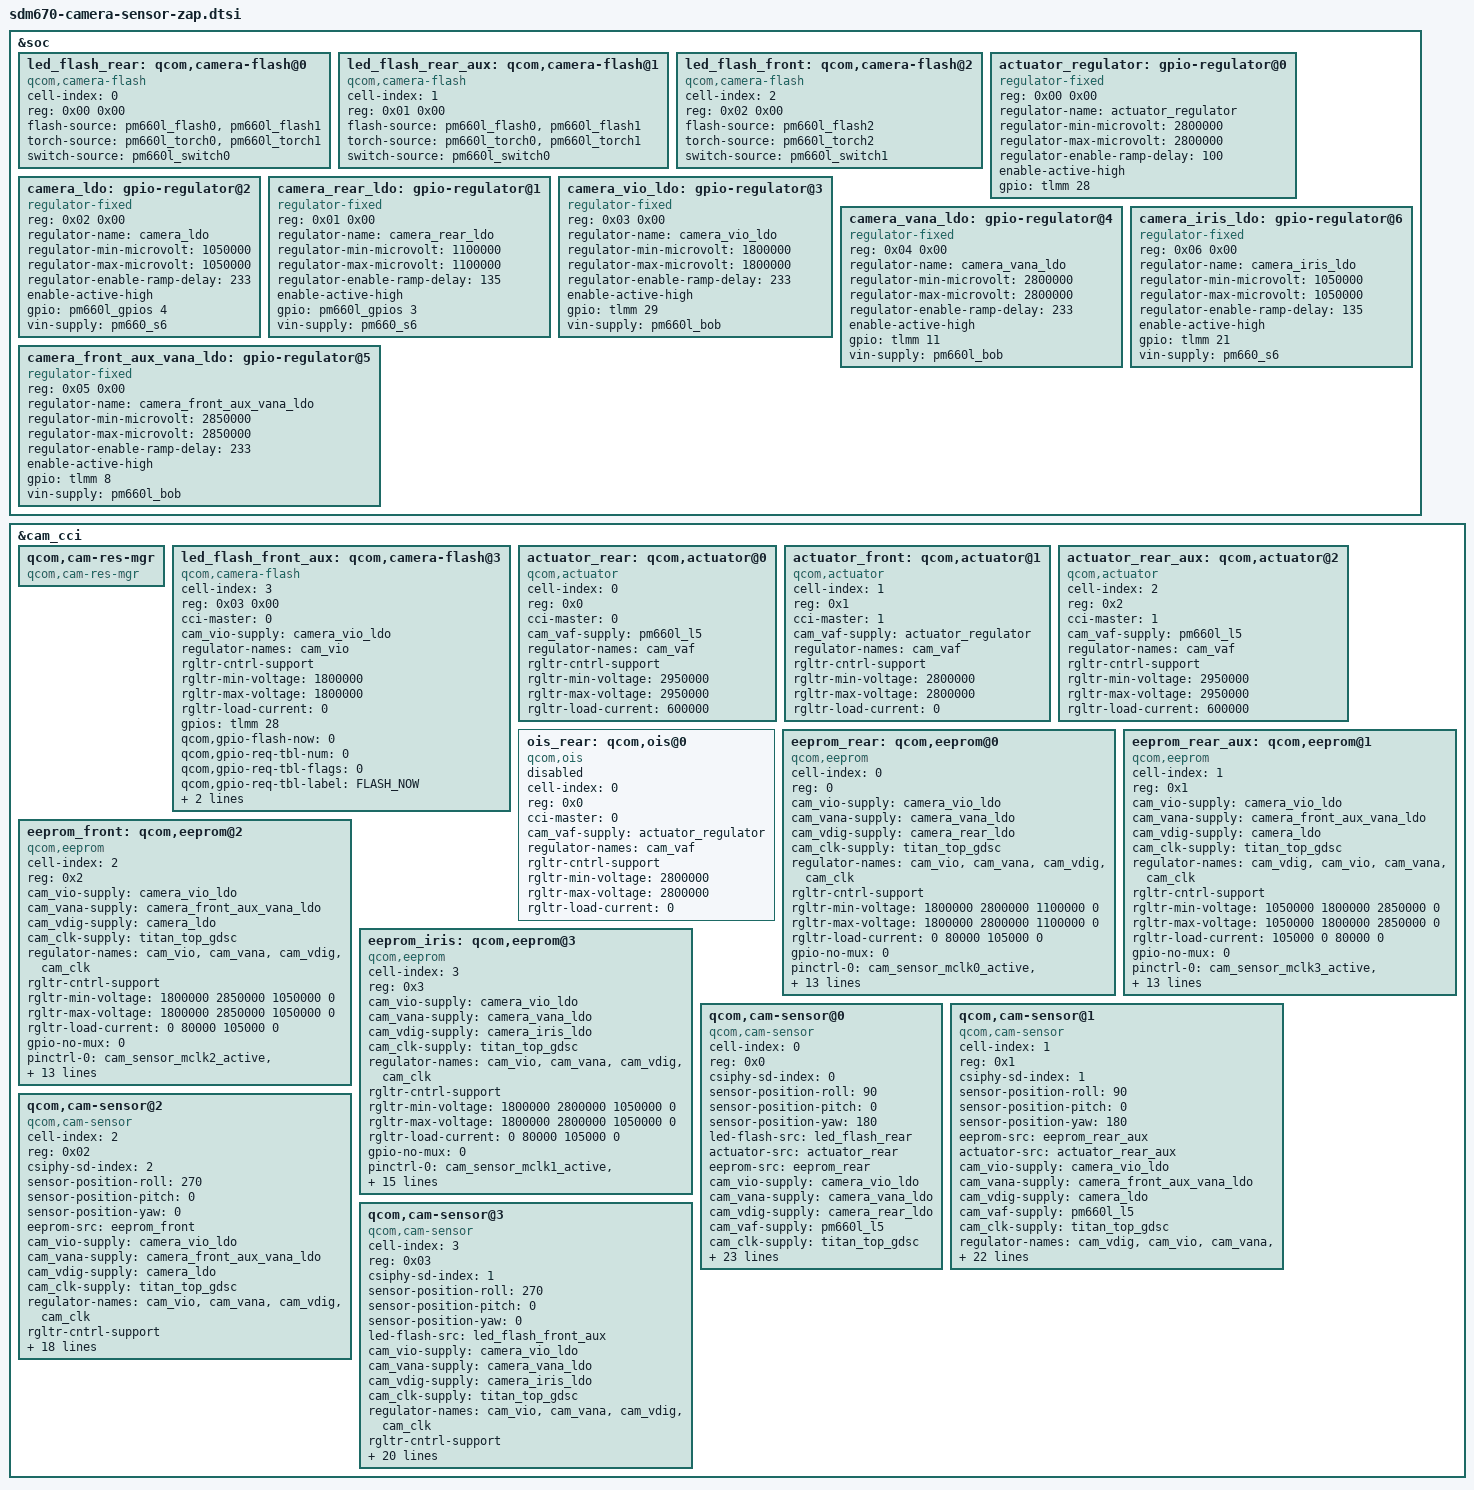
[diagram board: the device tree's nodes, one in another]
/*
 * Copyright (c) 2016-2018, The Linux Foundation. All rights reserved.
 *
 * This program is free software; you can redistribute it and/or modify
 * it under the terms of the GNU General Public License version 2 and
 * only version 2 as published by the Free Software Foundation.
 *
 * This program is distributed in the hope that it will be useful,
 * but WITHOUT ANY WARRANTY; without even the implied warranty of
 * MERCHANTABILITY or FITNESS FOR A PARTICULAR PURPOSE.  See the
 * GNU General Public License for more details.
 */

&soc {
/* Flash Led setting : start */
	led_flash_rear: qcom,camera-flash@0 {
		cell-index = <0>;
		reg = <0x00 0x00>;
		compatible = "qcom,camera-flash";
		flash-source = <&pm660l_flash0 &pm660l_flash1>;
		torch-source = <&pm660l_torch0 &pm660l_torch1>;
		switch-source = <&pm660l_switch0>;
		status = "ok";
	};

	led_flash_rear_aux: qcom,camera-flash@1 {
		cell-index = <1>;
		reg = <0x01 0x00>;
		compatible = "qcom,camera-flash";
		flash-source = <&pm660l_flash0 &pm660l_flash1>;
		torch-source = <&pm660l_torch0 &pm660l_torch1>;
		switch-source = <&pm660l_switch0>;
		status = "ok";
	};

	led_flash_front: qcom,camera-flash@2 {
		cell-index = <2>;
		reg = <0x02 0x00>;
		compatible = "qcom,camera-flash";
		flash-source = <&pm660l_flash2>;
		torch-source = <&pm660l_torch2>;
		switch-source = <&pm660l_switch1>;
		status = "ok";
	};
/*
	led_flash_iris: qcom,camera-flash@3 {
		cell-index = <3>;
		reg = <0x03 0x00>;
		compatible = "qcom,camera-flash";
		flash-source = <&pm660l_flash2>;
		torch-source = <&pm660l_torch2>;
		switch-source = <&pm660l_switch2>;
		status = "ok";
	};

*/
/* Flash Led setting : end */

/* actuator setting : start */
	actuator_regulator: gpio-regulator@0 {
		compatible = "regulator-fixed";
		reg = <0x00 0x00>;
		regulator-name = "actuator_regulator";
		regulator-min-microvolt = <2800000>;
		regulator-max-microvolt = <2800000>;
		regulator-enable-ramp-delay = <100>;
		enable-active-high;
		gpio = <&tlmm 28 0>;
	};
/* actuator setting : end */

/* Front&Aux DVDD : start */
	camera_ldo: gpio-regulator@2 {
		compatible = "regulator-fixed";
		reg = <0x02 0x00>;
		regulator-name = "camera_ldo";
		regulator-min-microvolt = <1050000>;
		regulator-max-microvolt = <1050000>;
		regulator-enable-ramp-delay = <233>;
		enable-active-high;
		gpio = <&pm660l_gpios 4 0>;
		/*pinctrl-names = "default";*/
		/*pinctrl-0 = <&camera_front_aux_dvdd_en_default>;*/
		vin-supply = <&pm660_s6>;
	};
/* Front&Aux DVDD : end */

/* Rear DVDD : start */
	camera_rear_ldo: gpio-regulator@1 {
		compatible = "regulator-fixed";
		reg = <0x01 0x00>;
		regulator-name = "camera_rear_ldo";
		regulator-min-microvolt = <1100000>;
		regulator-max-microvolt = <1100000>;
		regulator-enable-ramp-delay = <135>;
		enable-active-high;
		gpio = <&pm660l_gpios 3 0>;
		/*pinctrl-names = "default";*/
		/*pinctrl-0 = <&camera_rear_dvdd_en_default>;*/
		vin-supply = <&pm660_s6>;
	};
/* Rear DVDD : end */

/* all sensor DOVDD : start */
	camera_vio_ldo: gpio-regulator@3 {
		compatible = "regulator-fixed";
		reg = <0x03 0x00>;
		regulator-name = "camera_vio_ldo";
		regulator-min-microvolt = <1800000>;
		regulator-max-microvolt = <1800000>;
		regulator-enable-ramp-delay = <233>;
		enable-active-high;
		gpio = <&tlmm 29 0>;
		/*pinctrl-names = "default";*/
		/*pinctrl-0 = <&cam_sensor_rear_vio>;*/
		vin-supply = <&pm660l_bob>;
	};
/* all sensor DOVDD : end */

/* Rear&IR AVDD : start */
	camera_vana_ldo: gpio-regulator@4 {
		compatible = "regulator-fixed";
		reg = <0x04 0x00>;
		regulator-name = "camera_vana_ldo";
		regulator-min-microvolt = <2800000>;
		regulator-max-microvolt = <2800000>;
		regulator-enable-ramp-delay = <233>;
		enable-active-high;
		gpio = <&tlmm 11 0>;
		/*pinctrl-names = "default";*/
		/*pinctrl-0 = <&cam_sensor_rear_vana>;*/
		vin-supply = <&pm660l_bob>;
	};
/* Rear&IR AVDD : end */

/* Front&Aux AVDD : start */
	camera_front_aux_vana_ldo: gpio-regulator@5 {
		compatible = "regulator-fixed";
		reg = <0x05 0x00>;
		regulator-name = "camera_front_aux_vana_ldo";
		regulator-min-microvolt = <2850000>;
		regulator-max-microvolt = <2850000>;
		regulator-enable-ramp-delay = <233>;
		enable-active-high;
		gpio = <&tlmm 8 0>;
		/*pinctrl-names = "default";*/
		/*pinctrl-0 = <&cam_sensor_front_aux_vana>;*/
		vin-supply = <&pm660l_bob>;
	};
/* Front&Aux AVDD : end */

/* IR DVDD : start */
	camera_iris_ldo: gpio-regulator@6 {
		compatible = "regulator-fixed";
		reg = <0x06 0x00>;
		regulator-name = "camera_iris_ldo";
		regulator-min-microvolt = <1050000>;
		regulator-max-microvolt = <1050000>;
		regulator-enable-ramp-delay = <135>;
		enable-active-high;
		gpio = <&tlmm 21 0>;
		/*pinctrl-names = "default";*/
		/*pinctrl-0 = <&camera_rear_dvdd_en_default>;*/
		vin-supply = <&pm660_s6>;
	};
/* IR DVDD : end */
};

&cam_cci {
	qcom,cam-res-mgr {
		compatible = "qcom,cam-res-mgr";
		status = "ok";
	};

	led_flash_front_aux: qcom,camera-flash@3 {
		cell-index = <3>;
		reg = <0x03 0x00>;
		compatible = "qcom,camera-flash";
		cci-master = <0>;

        	cam_vio-supply = <&camera_vio_ldo>;
        	regulator-names = "cam_vio";
        	rgltr-cntrl-support;
        	rgltr-min-voltage = <1800000>;
        	rgltr-max-voltage = <1800000>;
        	rgltr-load-current = <0>;

		gpios = <&tlmm 28 0>;
		qcom,gpio-flash-now = <0>;
		qcom,gpio-req-tbl-num = <0>;
		qcom,gpio-req-tbl-flags = <0>;
		qcom,gpio-req-tbl-label = "FLASH_NOW";
		qcom,max-current = <1000>;
		qcom,max-duration = <1200>;
		status = "ok";
	};

	actuator_rear: qcom,actuator@0 {
		cell-index = <0>;
		reg = <0x0>;
		compatible = "qcom,actuator";
		cci-master = <0>;
		cam_vaf-supply = <&pm660l_l5>;
		regulator-names = "cam_vaf";
		rgltr-cntrl-support;
		rgltr-min-voltage = <2950000>;
		rgltr-max-voltage = <2950000>;
		rgltr-load-current = <600000>;
	};

	actuator_front: qcom,actuator@1 {
		cell-index = <1>;
		reg = <0x1>;
		compatible = "qcom,actuator";
		cci-master = <1>;
		cam_vaf-supply = <&actuator_regulator>;
		regulator-names = "cam_vaf";
		rgltr-cntrl-support;
		rgltr-min-voltage = <2800000>;
		rgltr-max-voltage = <2800000>;
		rgltr-load-current = <0>;
	};

	actuator_rear_aux: qcom,actuator@2 {
		cell-index = <2>;
		reg = <0x2>;
		compatible = "qcom,actuator";
		cci-master = <1>;
		cam_vaf-supply = <&pm660l_l5>;
		regulator-names = "cam_vaf";
		rgltr-cntrl-support;
		rgltr-min-voltage = <2950000>;
		rgltr-max-voltage = <2950000>;
		rgltr-load-current = <600000>;
	};

	ois_rear: qcom,ois@0 {
		cell-index = <0>;
		reg = <0x0>;
		compatible = "qcom,ois";
		cci-master = <0>;
		cam_vaf-supply = <&actuator_regulator>;
		regulator-names = "cam_vaf";
		rgltr-cntrl-support;
		rgltr-min-voltage = <2800000>;
		rgltr-max-voltage = <2800000>;
		rgltr-load-current = <0>;
		status = "disabled";
	};

	eeprom_rear: qcom,eeprom@0 {
		cell-index = <0>;
		reg = <0>;
		compatible = "qcom,eeprom";
		cam_vio-supply = <&camera_vio_ldo>;
		cam_vana-supply = <&camera_vana_ldo>;
		cam_vdig-supply = <&camera_rear_ldo>;
		cam_clk-supply = <&titan_top_gdsc>;
		regulator-names = "cam_vio", "cam_vana", "cam_vdig",
			"cam_clk";
		rgltr-cntrl-support;
		rgltr-min-voltage = <1800000 2800000 1100000 0>;
		rgltr-max-voltage = <1800000 2800000 1100000 0>;
		rgltr-load-current = <0 80000 105000 0>;
		gpio-no-mux = <0>;
		pinctrl-names = "cam_default", "cam_suspend";
		pinctrl-0 = <&cam_sensor_mclk0_active
				&cam_sensor_rear_active>;
		pinctrl-1 = <&cam_sensor_mclk0_suspend
				&cam_sensor_rear_suspend>;
		gpios = <&tlmm 13 0>,
			<&tlmm 30 0>;
		gpio-reset = <1>;
		gpio-req-tbl-num = <0 1>;
		gpio-req-tbl-flags = <1 0>;
		gpio-req-tbl-label = "CAMIF_MCLK0",
					"CAM_RESET0";
		sensor-mode = <0>;
		cci-master = <0>;
		status = "ok";
		clocks = <&clock_camcc CAM_CC_MCLK0_CLK>;
		clock-names = "cam_clk";
		clock-cntl-level = "turbo";
		clock-rates = <24000000>;
	};

	eeprom_rear_aux: qcom,eeprom@1 {
		cell-index = <1>;
		reg = <0x1>;
		compatible = "qcom,eeprom";
		cam_vio-supply = <&camera_vio_ldo>;
		cam_vana-supply = <&camera_front_aux_vana_ldo>;
		cam_vdig-supply = <&camera_ldo>;
		cam_clk-supply = <&titan_top_gdsc>;
		regulator-names = "cam_vdig", "cam_vio", "cam_vana",
			"cam_clk";
		rgltr-cntrl-support;
		rgltr-min-voltage = <1050000 1800000 2850000 0>;
		rgltr-max-voltage = <1050000 1800000 2850000 0>;
		rgltr-load-current = <105000 0 80000 0>;
		gpio-no-mux = <0>;
		pinctrl-names = "cam_default", "cam_suspend";
		pinctrl-0 = <&cam_sensor_mclk3_active
				&cam_sensor_rear2_active>;
		pinctrl-1 = <&cam_sensor_mclk3_suspend
				&cam_sensor_rear2_suspend>;
		gpios = <&tlmm 16 0>,
			<&tlmm 23 0>;
		gpio-reset = <1>;
		gpio-req-tbl-num = <0 1>;
		gpio-req-tbl-flags = <1 0>;
		gpio-req-tbl-label = "CAMIF_MCLK3",
					"CAM_RESET3";
		sensor-mode = <0>;
		cci-master = <1>;
		status = "ok";
		clocks = <&clock_camcc CAM_CC_MCLK3_CLK>;
		clock-names = "cam_clk";
		clock-cntl-level = "turbo";
		clock-rates = <24000000>;
	};

	eeprom_front: qcom,eeprom@2 {
		cell-index = <2>;
		reg = <0x2>;
		compatible = "qcom,eeprom";
		cam_vio-supply = <&camera_vio_ldo>;
		cam_vana-supply = <&camera_front_aux_vana_ldo>;
		cam_vdig-supply = <&camera_ldo>;
		cam_clk-supply = <&titan_top_gdsc>;
		regulator-names = "cam_vio", "cam_vana", "cam_vdig",
			"cam_clk";
		rgltr-cntrl-support;
		rgltr-min-voltage = <1800000 2850000 1050000 0>;
		rgltr-max-voltage = <1800000 2850000 1050000 0>;
		rgltr-load-current = <0 80000 105000 0>;
		gpio-no-mux = <0>;
		pinctrl-names = "cam_default", "cam_suspend";
		pinctrl-0 = <&cam_sensor_mclk2_active
				 &cam_sensor_front_active>;
		pinctrl-1 = <&cam_sensor_mclk2_suspend
				 &cam_sensor_front_suspend>;
		gpios = <&tlmm 15 0>,
			<&tlmm 9 0>;
		gpio-reset = <1>;
		gpio-req-tbl-num = <0 1>;
		gpio-req-tbl-flags = <1 0>;
		gpio-req-tbl-label = "CAMIF_MCLK2",
					"CAM_RESET2";
		sensor-mode = <0>;
		cci-master = <1>;
		status = "ok";
		clocks = <&clock_camcc CAM_CC_MCLK2_CLK>;
		clock-names = "cam_clk";
		clock-cntl-level = "turbo";
		clock-rates = <24000000>;
	};

	eeprom_iris: qcom,eeprom@3 {
		cell-index = <3>;
		reg = <0x3>;
		compatible = "qcom,eeprom";
		cam_vio-supply = <&camera_vio_ldo>;
		cam_vana-supply = <&camera_vana_ldo>;
		cam_vdig-supply = <&camera_iris_ldo>;
		cam_clk-supply = <&titan_top_gdsc>;
		regulator-names = "cam_vio", "cam_vana", "cam_vdig",
			"cam_clk";
		rgltr-cntrl-support;
		rgltr-min-voltage = <1800000 2800000 1050000 0>;
		rgltr-max-voltage = <1800000 2800000 1050000 0>;
		rgltr-load-current = <0 80000 105000 0>;
		gpio-no-mux = <0>;
		pinctrl-names = "cam_default", "cam_suspend";
		pinctrl-0 = <&cam_sensor_mclk1_active
				 &cam_sensor_iris_active>;
		pinctrl-1 = <&cam_sensor_mclk1_suspend
				 &cam_sensor_iris_suspend>;
		gpios = <&tlmm 14 0>,
			<&tlmm 89 0>,
			<&tlmm 25 0>;
		gpio-reset = <1>;
		gpio-custom1 = <2>;
		gpio-req-tbl-num = <0 1 2>;
		gpio-req-tbl-flags = <1 0 0>;
		gpio-req-tbl-label = "CAMIF_MCLK1",
					"CAM_RESET1",
					"CAM_CUSTOM1";
		sensor-mode = <0>;
		cci-master = <0>;
		status = "ok";
		clocks = <&clock_camcc CAM_CC_MCLK1_CLK>;
		clock-names = "cam_clk";
		clock-cntl-level = "turbo";
		clock-rates = <24000000>;
	};

	qcom,cam-sensor@0 {
		cell-index = <0>;
		compatible = "qcom,cam-sensor";
		reg = <0x0>;
		csiphy-sd-index = <0>;
		sensor-position-roll = <90>;
		sensor-position-pitch = <0>;
		sensor-position-yaw = <180>;
		led-flash-src = <&led_flash_rear>;
		actuator-src = <&actuator_rear>;
		eeprom-src = <&eeprom_rear>;
		cam_vio-supply = <&camera_vio_ldo>;
		cam_vana-supply = <&camera_vana_ldo>;
		cam_vdig-supply = <&camera_rear_ldo>;
		cam_vaf-supply = <&pm660l_l5>;
		cam_clk-supply = <&titan_top_gdsc>;
		regulator-names = "cam_vio", "cam_vana", "cam_vdig", "cam_vaf",
			"cam_clk";
		rgltr-cntrl-support;
		rgltr-min-voltage = <1800000 2800000 1100000 2950000 0>;
		rgltr-max-voltage = <1800000 2800000 1100000 2950000 0>;
		rgltr-load-current = <0 80000 105000 600000 0>;
		gpio-no-mux = <0>;
		pinctrl-names = "cam_default", "cam_suspend";
		pinctrl-0 = <&cam_sensor_mclk0_active
				&cam_sensor_rear_active>;
		pinctrl-1 = <&cam_sensor_mclk0_suspend
				&cam_sensor_rear_suspend>;
		gpios = <&tlmm 13 0>,
			<&tlmm 30 0>;
		gpio-reset = <1>;
		gpio-req-tbl-num = <0 1>;
		gpio-req-tbl-flags = <1 0>;
		gpio-req-tbl-label = "CAMIF_MCLK0",
					"CAM_RESET0";
		sensor-mode = <0>;
		cci-master = <0>;
		status = "ok";
		clocks = <&clock_camcc CAM_CC_MCLK0_CLK>;
		clock-names = "cam_clk";
		clock-cntl-level = "turbo";
		clock-rates = <24000000>;
	};

	qcom,cam-sensor@1 {
		cell-index = <1>;
		compatible = "qcom,cam-sensor";
		reg = <0x1>;
		csiphy-sd-index = <1>;
		sensor-position-roll = <90>;
		sensor-position-pitch = <0>;
		sensor-position-yaw = <180>;
		/*led-flash-src = <&led_flash_rear_aux>;*/
		eeprom-src = <&eeprom_rear_aux>;
		actuator-src = <&actuator_rear_aux>;
		cam_vio-supply = <&camera_vio_ldo>;
		cam_vana-supply = <&camera_front_aux_vana_ldo>;
		cam_vdig-supply = <&camera_ldo>;
		cam_vaf-supply = <&pm660l_l5>;
		cam_clk-supply = <&titan_top_gdsc>;
		regulator-names = "cam_vdig", "cam_vio", "cam_vana", "cam_vaf",
			"cam_clk";
		rgltr-cntrl-support;
		rgltr-min-voltage = <1050000 1800000 2850000 2950000 0>;
		rgltr-max-voltage = <1050000 1800000 2850000 2950000 0>;
		rgltr-load-current = <105000 0 80000 600000 0>;
		gpio-no-mux = <0>;
		pinctrl-names = "cam_default", "cam_suspend";
		pinctrl-0 = <&cam_sensor_mclk3_active
				&cam_sensor_rear2_active>;
		pinctrl-1 = <&cam_sensor_mclk3_suspend
				&cam_sensor_rear2_suspend>;
		gpios = <&tlmm 16 0>,
			<&tlmm 23 0>;
		gpio-reset = <1>;
		gpio-req-tbl-num = <0 1>;
		gpio-req-tbl-flags = <1 0>;
		gpio-req-tbl-label = "CAMIF_MCLK3",
					"CAM_RESET3";
		sensor-mode = <0>;
		cci-master = <1>;
		status = "ok";
		clocks = <&clock_camcc CAM_CC_MCLK3_CLK>;
		clock-names = "cam_clk";
		clock-cntl-level = "turbo";
		clock-rates = <24000000>;
	};

	qcom,cam-sensor@2 {
		cell-index = <2>;
		compatible = "qcom,cam-sensor";
		reg = <0x02>;
		csiphy-sd-index = <2>;
		sensor-position-roll = <270>;
		sensor-position-pitch = <0>;
		sensor-position-yaw = <0>;
		eeprom-src = <&eeprom_front>;
		/*led-flash-src = <&led_flash_front>;*/
		cam_vio-supply = <&camera_vio_ldo>;
		cam_vana-supply = <&camera_front_aux_vana_ldo>;
		cam_vdig-supply = <&camera_ldo>;
		cam_clk-supply = <&titan_top_gdsc>;
		regulator-names = "cam_vio", "cam_vana", "cam_vdig",
			"cam_clk";
		rgltr-cntrl-support;
		rgltr-min-voltage = <1800000 2850000 1050000 0>;
		rgltr-max-voltage = <1800000 2850000 1050000 0>;
		rgltr-load-current = <0 80000 105000 0>;
		gpio-no-mux = <0>;
		pinctrl-names = "cam_default", "cam_suspend";
		pinctrl-0 = <&cam_sensor_mclk2_active
				 &cam_sensor_front_active>;
		pinctrl-1 = <&cam_sensor_mclk2_suspend
				 &cam_sensor_front_suspend>;
		gpios = <&tlmm 15 0>,
			<&tlmm 9 0>;
		gpio-reset = <1>;
		gpio-req-tbl-num = <0 1>;
		gpio-req-tbl-flags = <1 0>;
		gpio-req-tbl-label = "CAMIF_MCLK2",
					"CAM_RESET2";
		sensor-mode = <0>;
		cci-master = <1>;
		status = "ok";
		clocks = <&clock_camcc CAM_CC_MCLK2_CLK>;
		clock-names = "cam_clk";
		clock-cntl-level = "turbo";
		clock-rates = <24000000>;
	};

	qcom,cam-sensor@3 {
		cell-index = <3>;
		compatible = "qcom,cam-sensor";
		reg = <0x03>;
		csiphy-sd-index = <1>;
		sensor-position-roll = <270>;
		sensor-position-pitch = <0>;
		sensor-position-yaw = <0>;
		/* eeprom-src = <&eeprom_iris>;*/
		/*actuator-src = <&actuator_iris>;*/
		led-flash-src = <&led_flash_front_aux>;
		cam_vio-supply = <&camera_vio_ldo>;
		cam_vana-supply = <&camera_vana_ldo>;
		cam_vdig-supply = <&camera_iris_ldo>;
		cam_clk-supply = <&titan_top_gdsc>;
		regulator-names = "cam_vio", "cam_vana", "cam_vdig",
			"cam_clk";
		rgltr-cntrl-support;
		rgltr-min-voltage = <1800000 2800000 1050000 0>;
		rgltr-max-voltage = <1800000 2800000 1050000 0>;
		rgltr-load-current = <0 80000 105000 0>;
		gpio-no-mux = <0>;
		pinctrl-names = "cam_default", "cam_suspend";
		pinctrl-0 = <&cam_sensor_mclk1_active
				 &cam_sensor_iris_active>;
		pinctrl-1 = <&cam_sensor_mclk1_suspend
				 &cam_sensor_iris_suspend>;
		gpios = <&tlmm 14 0>,
			<&tlmm 89 0>,
			<&tlmm 25 0>;
		gpio-reset = <1>;
		gpio-custom1 = <2>;
		gpio-req-tbl-num = <0 1 2>;
		gpio-req-tbl-flags = <1 0 0>;
		gpio-req-tbl-label = "CAMIF_MCLK1",
					"CAM_RESET1",
					"CAM_CUSTOM1";
		sensor-mode = <0>;
		cci-master = <0>;
		status = "ok";
		clocks = <&clock_camcc CAM_CC_MCLK1_CLK>;
		clock-names = "cam_clk";
		clock-cntl-level = "turbo";
		clock-rates = <24000000>;
	};
};
